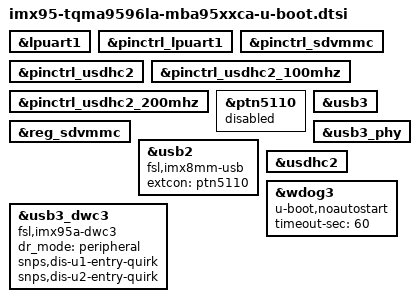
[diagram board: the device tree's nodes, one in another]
// SPDX-License-Identifier: (GPL-2.0-or-later OR MIT)
/*
 * Copyright (c) 2026 TQ-Systems GmbH <u-boot@ew.tq-group.com>,
 * D-82229 Seefeld, Germany.
 * Author: Markus Niebel
 */

#include "imx95-tqma9596la-u-boot.dtsi"

&lpuart1 {
	bootph-pre-ram;
};

&pinctrl_lpuart1 {
	bootph-pre-ram;
};

&pinctrl_sdvmmc {
	bootph-pre-ram;
};

&pinctrl_usdhc2 {
	bootph-pre-ram;
};

&pinctrl_usdhc2_100mhz {
	bootph-pre-ram;
};

&pinctrl_usdhc2_200mhz {
	bootph-pre-ram;
};

&ptn5110 {
	status = "disabled";
	/delete-node/ connector;
};

&reg_sdvmmc {
	bootph-pre-ram;
};

&usb2 {
	/delete-node/ port;
};

&usb2 {
	compatible = "fsl,imx8mm-usb", "fsl,imx7d-usb";
	/delete-property/ power-domains;
	/* needed for dual role / board phy mode */
	extcon = <&ptn5110>;
};

&usb3 {
	/delete-property/ power-domains;
};

/*
 * Peripheral for serial download mode
 * adjusted in board_fix_fdt
 */
&usb3_dwc3 {
	compatible = "fsl,imx95a-dwc3", "fsl,imx8mq-dwc3", "snps,dwc3";
	dr_mode = "peripheral";
	snps,dis-u1-entry-quirk;
	snps,dis-u2-entry-quirk;
};

&usb3_phy {
	/*
	 * not supported, in U-Boot, enabled in board_usb_init if !usb boot
	 */
	/delete-property/ vbus-supply;
};

&usdhc2 {
	bootph-pre-ram;
};

&wdog3 {
	u-boot,noautostart;
	timeout-sec = <60>;
};
